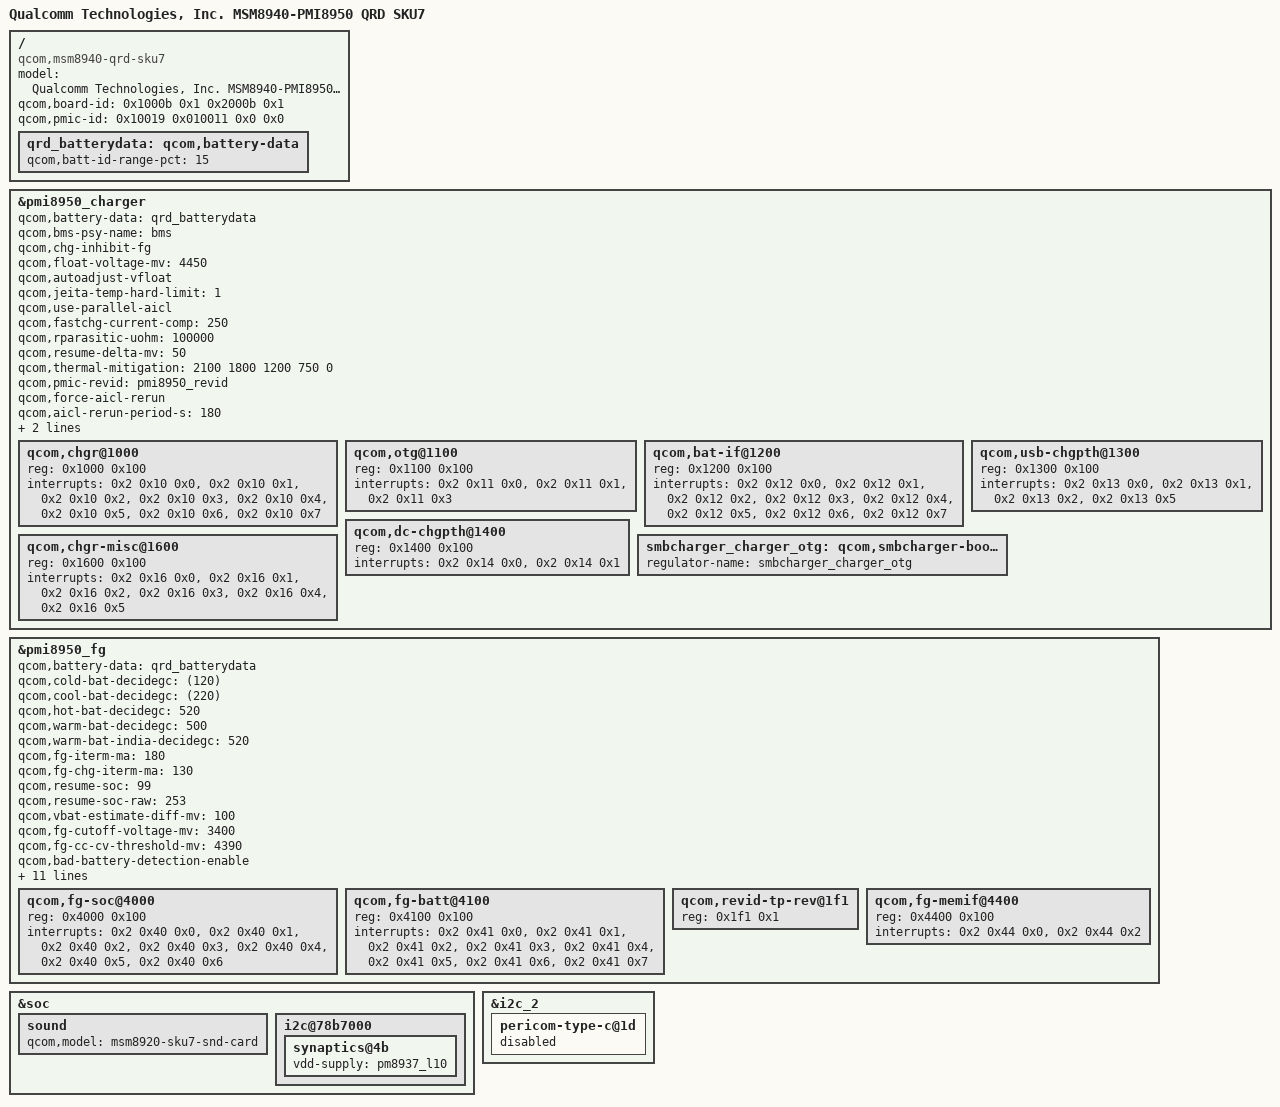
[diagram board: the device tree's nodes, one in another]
/*
 * Copyright (c) 2016, The Linux Foundation. All rights reserved.
 *
 * This program is free software; you can redistribute it and/or modify
 * it under the terms of the GNU General Public License version 2 and
 * only version 2 as published by the Free Software Foundation.
 *
 * This program is distributed in the hope that it will be useful,
 * but WITHOUT ANY WARRANTY; without even the implied warranty of
 * MERCHANTABILITY or FITNESS FOR A PARTICULAR PURPOSE.  See the
 * GNU General Public License for more details.
 */

/dts-v1/;

#include "msm8940.dtsi"
#include "msm8937-pmi8950-qrd-sku1.dtsi"
#include "msm8940-camera-sensor-qrd.dtsi"
#include "msm8940-pinctrl.dtsi"

/ {
	model = "Qualcomm Technologies, Inc. MSM8940-PMI8950 QRD SKU7";
	compatible = "qcom,msm8940-qrd-sku7", "qcom,msm8940-qrd",
		   "qcom,msm8940", "qcom,qrd";
	qcom,board-id= <0x1000b 0x1 0x2000b 0x1>;
	qcom,pmic-id = <0x10019 0x010011 0x0 0x0>;
};

/ {
	qrd_batterydata: qcom,battery-data {
		qcom,batt-id-range-pct = <15>;
		#include "batterydata-qrd-Desay-4v4-4000mah.dtsi"
		#include "batterydata-qrd-Atl-4v4-4000mah.dtsi"
		#include "batterydata-qrd-Coslight-4v4-4000mah.dtsi"
		#include "batterydata-qrd-Default-4v4-40000mah.dtsi"
	};
};

&pmi8950_charger {
	qcom,battery-data = <&qrd_batterydata>;
	qcom,bms-psy-name = "bms";
	qcom,chg-inhibit-fg;
	qcom,float-voltage-mv = <4450>;
	qcom,autoadjust-vfloat;
	qcom,jeita-temp-hard-limit = <1>;
	qcom,use-parallel-aicl;
	qcom,fastchg-current-comp = <250>;
	qcom,rparasitic-uohm = <100000>;
	qcom,resume-delta-mv = <50>;
	qcom,thermal-mitigation = <2100 1800 1200 750 0>;
	qcom,pmic-revid = <&pmi8950_revid>;
	qcom,force-aicl-rerun;
	qcom,aicl-rerun-period-s = <180>;
	status = "okay";
	qcom,vchg_sns-vadc = <&pmi8950_vadc>;
	qcom,vchg-adc-channel-id = <0x3>;

			qcom,chgr@1000 {
				reg = <0x1000 0x100>;
				interrupts =	<0x2 0x10 0x0>,
						<0x2 0x10 0x1>,
						<0x2 0x10 0x2>,
						<0x2 0x10 0x3>,
						<0x2 0x10 0x4>,
						<0x2 0x10 0x5>,
						<0x2 0x10 0x6>,
						<0x2 0x10 0x7>;

				interrupt-names =	"chg-error",
							"chg-inhibit",
							"chg-prechg-sft",
							"chg-complete-chg-sft",
							"chg-p2f-thr",
							"chg-rechg-thr",
							"chg-taper-thr",
							"chg-tcc-thr";
			};

			qcom,otg@1100 {
				reg = <0x1100 0x100>;
				interrupts =	<0x2 0x11 0x0>,
						<0x2 0x11 0x1>,
						<0x2 0x11 0x3>;
				interrupt-names =	"otg-fail",
							"otg-oc",
						"usbid-change";
			};

			qcom,bat-if@1200 {
				reg = <0x1200 0x100>;
				interrupts =	<0x2 0x12 0x0>,
						<0x2 0x12 0x1>,
						<0x2 0x12 0x2>,
						<0x2 0x12 0x3>,
					<0x2 0x12 0x4>,
						<0x2 0x12 0x5>,
						<0x2 0x12 0x6>,
						<0x2 0x12 0x7>;

				interrupt-names =	"batt-hot",
							"batt-warm",
							"batt-cold",
							"batt-cool",
						"batt-ov",
							"batt-low",
							"batt-missing",
							"batt-term-missing";
			};

			qcom,usb-chgpth@1300 {
				reg = <0x1300 0x100>;
				interrupts =	<0x2 0x13 0x0>,
						<0x2 0x13 0x1>,
					<0x2 0x13 0x2>,
						<0x2 0x13 0x5>;

				interrupt-names =	"usbin-uv",
						"usbin-ov",
							"usbin-src-det",
							"aicl-done";
			};

			qcom,dc-chgpth@1400 {
				reg = <0x1400 0x100>;
				interrupts =	<0x2 0x14 0x0>,
						<0x2 0x14 0x1>;
				interrupt-names =	"dcin-uv",
							"dcin-ov";
			};

			qcom,chgr-misc@1600 {
				reg = <0x1600 0x100>;
				interrupts =	<0x2 0x16 0x0>,
						<0x2 0x16 0x1>,
						<0x2 0x16 0x2>,
					<0x2 0x16 0x3>,
						<0x2 0x16 0x4>,
						<0x2 0x16 0x5>;

				interrupt-names =	"power-ok",
							"temp-shutdown",
							"wdog-timeout",
							"flash-fail",
							"otst2",
							"otst3";
			};

			smbcharger_charger_otg: qcom,smbcharger-boost-otg {
				regulator-name = "smbcharger_charger_otg";
			};
};

&pmi8950_fg {
	qcom,battery-data = <&qrd_batterydata>;
	qcom,cold-bat-decidegc = <(120)>;
	qcom,cool-bat-decidegc = <(220)>;
	qcom,hot-bat-decidegc = <520>;
	qcom,warm-bat-decidegc = <500>;
	qcom,warm-bat-india-decidegc = <520>;
	qcom,fg-iterm-ma = <180>;
	qcom,fg-chg-iterm-ma = <130>;
	qcom,resume-soc = <99>;
	qcom,resume-soc-raw = <253>;
	qcom,vbat-estimate-diff-mv = <100>;
	qcom,fg-cutoff-voltage-mv = <3400>;
	qcom,fg-cc-cv-threshold-mv = <4390>;
	qcom,bad-battery-detection-enable;
	qcom,capacity-estimation-on;
	qcom,esr-pulse-tuning-en;
	qcom,hold-soc-while-full;
	qcom,cycle-counter-en;
	qcom,capacity-learning-on;
	qcom,capacity-learning-feedback;
	qcom,cl-max-increment-deciperc = <1>;
	qcom,cl-max-decrement-deciperc = <1>;
	qcom,fg-delta-soc = <1>;
	qcom,bad-battery-detection-enable;
	qcom,hold-soc-while-full;
	qcom,pmic-revid = <&pmi8950_revid>;
	qcom,thermal-coefficients = [b7 85 b2 49 71 35];
	
	qcom,fg-soc@4000 {
			status = "okay";
				reg = <0x4000 0x100>;
				interrupts =	<0x2 0x40 0x0>,
						<0x2 0x40 0x1>,
						<0x2 0x40 0x2>,
						<0x2 0x40 0x3>,
						<0x2 0x40 0x4>,
						<0x2 0x40 0x5>,
						<0x2 0x40 0x6>;

				interrupt-names =	"high-soc",
							"low-soc",
							"full-soc",
							"empty-soc",
							"delta-soc",
							"first-est-done",
							"update-soc";
			};

			qcom,fg-batt@4100 {
				reg = <0x4100 0x100>;
				interrupts =	<0x2 0x41 0x0>,
						<0x2 0x41 0x1>,
					<0x2 0x41 0x2>,
						<0x2 0x41 0x3>,
						<0x2 0x41 0x4>,
						<0x2 0x41 0x5>,
						<0x2 0x41 0x6>,
						<0x2 0x41 0x7>;

				interrupt-names =	"soft-cold",
							"soft-hot",
							"vbatt-low",
							"batt-ided",
							"batt-id-req",
							"batt-unknown",
							"batt-missing",
							"batt-match";
			};

			qcom,revid-tp-rev@1f1 {
				reg = <0x1f1 0x1>;
			};

			qcom,fg-memif@4400 {
				status = "okay";
				reg = <0x4400 0x100>;
				interrupts =	<0x2 0x44 0x0>,
						<0x2 0x44 0x2>;

				interrupt-names =	"mem-avail",
							"data-rcvry-sug";
			};	
};

&soc {
	sound {
		qcom,model = "msm8920-sku7-snd-card";
	};

	i2c@78b7000 {
		synaptics@4b {
			vdd-supply = <&pm8937_l10>;
		};
	};
};

&i2c_2 {
	pericom-type-c@1d {
		status="disabled";
	};
};
